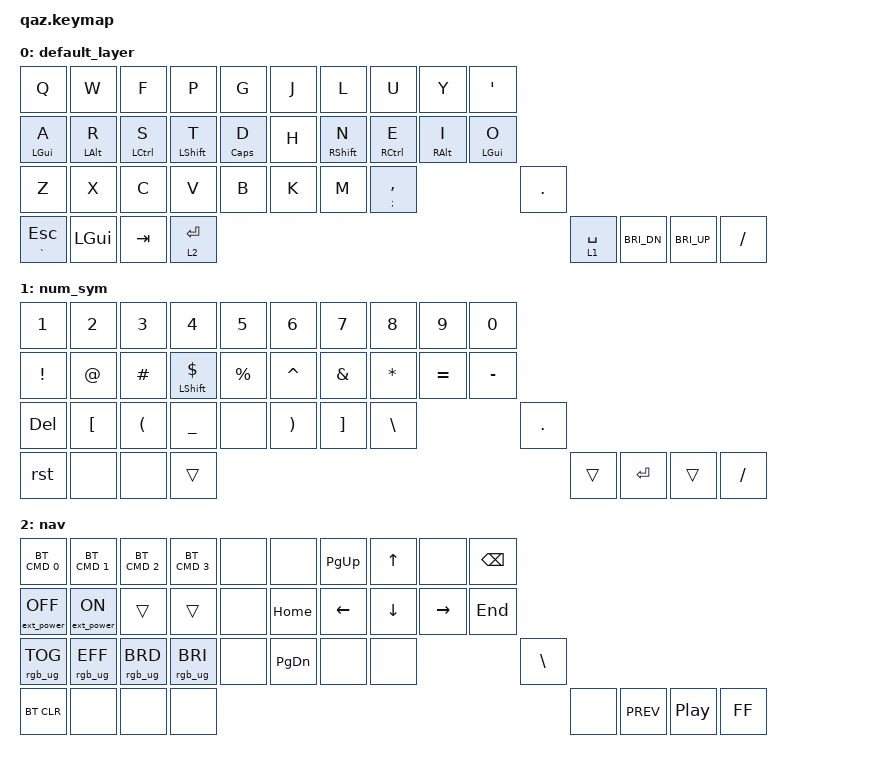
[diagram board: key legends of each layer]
/*
 * Copyright (c) 2020 The ZMK Contributors
 *
 * SPDX-License-Identifier: MIT
 */

#include <behaviors.dtsi>
#include <dt-bindings/zmk/keys.h>
#include <dt-bindings/zmk/bt.h>
#include <dt-bindings/zmk/rgb.h>
#include <dt-bindings/zmk/ext_power.h>

#define DEFAULT 0
#define NUM_SYM 1
#define NAV     2

/ {
	behaviors {
		rst: behavior_tap_hold1 {
			compatible = "zmk,behavior-hold-tap";
			label = "Bootloader Tap - Reset Hold";
			#binding-cells = <2>;
			tapping_term_ms = <200>;
            flavor = "balanced";
			bindings = <&reset>, <&bootloader>;
        };

        bh: layer_taps {
			compatible = "zmk,behavior-hold-tap";
			label = "Layer-Tap";
			#binding-cells = <2>;
			tapping_term_ms = <225>;
            flavor = "balanced";
			bindings = <&mo>, <&kp>;
        };

        hm: homerow_mods {
			compatible = "zmk,behavior-hold-tap";
			label = "homerow mods";
			#binding-cells = <2>;
			tapping_term_ms = <200>;
            flavor = "tap-preferred";
			bindings = <&kp>, <&kp>;
        };
        
        hm1: homerow_mods1 {
			compatible = "zmk,behavior-hold-tap";
			label = "homerow mods";
			#binding-cells = <2>;
			tapping_term_ms = <210>;
            flavor = "balanced";
			bindings = <&kp>, <&kp>;
        };

        hm2: homerow_mods2 {
			compatible = "zmk,behavior-hold-tap";
			label = "homerow mods 2";
			#binding-cells = <2>;
			tapping_term_ms = <230>;
            flavor = "tap-preferred";
			bindings = <&kp>, <&kp>;
        };

        com_col: behavior_tap_hold10 {
		 	compatible = "zmk,behavior-hold-tap";
	     	label = "Tap comma_hold colon";
			#binding-cells = <2>;
			tapping_term_ms = <150>;
            flavor = "balanced";
		 	bindings = <&kp>, <&kp>;
	     	};
	combo_one {
			compatible = "zmk,behavior-combo";
			label = "COMBO_ONE";
			timeout-ms = <30>;
			key-positions = <8 9>;
			bindings = <&kp BSPC>;
		};
        combo_two {
			compatible = "zmk,behavior-combo";
			label = "COMBO_TWO";
			timeout-ms = <30>;
			key-positions = <0 1>;
			bindings = <&com_col GRAVE ESC>;
		};
	combo_three {
			compatible = "zmk,behavior-combo";
			label = "COMBO_THREE";
			timeout-ms = <30>;
			key-positions = <11 12>;
			bindings = <&kp TAB>;
		};
		combo_four {
			compatible = "zmk,behavior-combo";
			label = "COMBO_FOUR";
			timeout-ms = <30>;
			key-positions = <35 36>;
			bindings = <&kp C_NEXT>;
		};
     combo_five {
			compatible = "zmk,behavior-combo";
			label = "COMBO_FIVE";
			timeout-ms = <30>;
			key-positions = <34 35>;
			bindings = <&kp C_PREV>;
		};
        combo_six {
			compatible = "zmk,behavior-combo";
			label = "COMBO_SIX";
			timeout-ms = <30>;
			key-positions = <34 36>;
			bindings = <&kp C_PP>;
		};
		combo_seven {
			compatible = "zmk,behavior-combo";
			label = "COMBO_SEVEN";
			timeout-ms = <30>;
			key-positions = <7 8 9>;
			bindings = <&kp DEL>;
		};
        };
    };

/ {
    keymap {
        compatible = "zmk,keymap";

        default_layer {
            bindings = <
    &kp Q &kp W &kp F &kp P &kp G &kp J &kp L &kp U &kp Y &kp SQT    
    &hm2 LGUI A &hm LALT R &hm LCTRL S &hm1 LSHFT T &hm2 CLCK D &kp H &hm1 RSHFT N &hm RCTRL E &hm RALT I &hm2 LGUI O
    &kp Z &kp X &kp C &kp V &kp B &kp K &kp M &com_col SEMI COMMA &kp DOT
    &com_col GRAVE ESC &kp LGUI &kp TAB &bh 2 RET &bh 1 SPACE &kp C_BRI_DN &kp C_BRI_UP &kp FSLH
            >;
        };

        num_sym {
            bindings = <
    &kp N1 &kp N2 &kp N3 &kp N4 &kp N5 &kp N6 &kp N7 &kp N8 &kp N9 &kp N0    
    &kp EXCL &kp AT &kp POUND &hm LSHFT DLLR &kp PRCNT &kp CARET &kp AMPS &kp STAR &kp EQUAL &kp MINUS       
    &kp DEL &kp LBKT &kp LPAR &kp UNDER &none &kp RPAR &kp RBKT &kp BSLH &kp DOT
    &rst &none &none &trans &trans &kp RET &trans &kp FSLH
            >;
        };

    nav {
            bindings = <
    &bt BT_SEL_CMD 0 &bt BT_SEL_CMD 1 &bt BT_SEL_CMD 2 &bt BT_SEL_CMD 3 &none &none &kp PG_UP &kp UP &none &kp BSPC    
    &ext_power EP_OFF &ext_power EP_ON &trans &trans &none &kp HOME &kp LEFT &kp DOWN &kp RIGHT &kp END       
    &rgb_ug RGB_TOG &rgb_ug RGB_EFF &rgb_ug RGB_BRD &rgb_ug RGB_BRI &none &kp PG_DN &none &none &kp BSLH
    &bt BT_CLR &none &none &none &none &kp C_PREV &kp C_PP &kp C_FF
            >;
        };
    };
};
